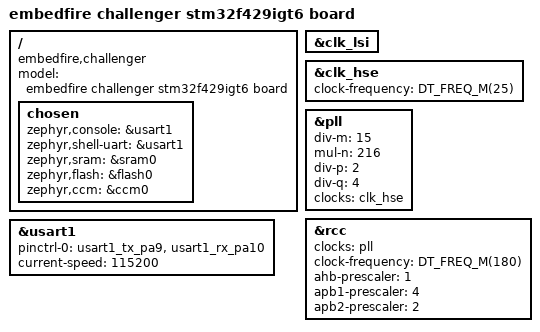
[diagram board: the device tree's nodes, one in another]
/dts-v1/;
#include <st/f4/stm32f429Xi.dtsi>
#include <st/f4/stm32f429i(e-g-i)hx-pinctrl.dtsi>
#include <zephyr/dt-bindings/input/input-event-codes.h>

/ {
    model = "embedfire challenger stm32f429igt6 board";
    compatible = "embedfire,challenger";

    chosen {
		zephyr,console = &usart1;
		zephyr,shell-uart = &usart1;
		zephyr,sram = &sram0;
		zephyr,flash = &flash0;
        zephyr,ccm = &ccm0;
    };
};

&clk_lsi {
	status = "okay";
};

&clk_hse {
	clock-frequency = <DT_FREQ_M(25)>;
	status = "okay";
};

&pll {
	div-m = <15>;
	mul-n = <216>;
	div-p = <2>;
	div-q = <4>;
	clocks = <&clk_hse>;
	status = "okay";
};

&rcc {
	clocks = <&pll>;
	clock-frequency = <DT_FREQ_M(180)>;
	ahb-prescaler = <1>;
	apb1-prescaler = <4>;
	apb2-prescaler = <2>;
};

&usart1 {
	pinctrl-0 = <&usart1_tx_pa9 &usart1_rx_pa10>;
	pinctrl-names = "default";
	current-speed = <115200>;
	status = "okay";
};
